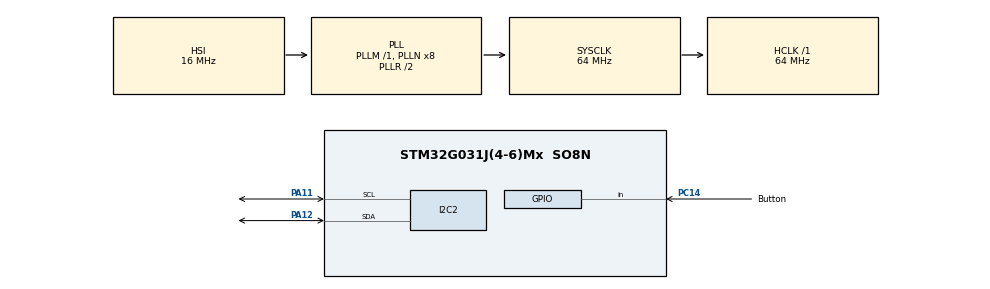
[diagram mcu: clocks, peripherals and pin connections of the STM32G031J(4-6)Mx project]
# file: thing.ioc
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I2C2.Timing=0x10707DBC
Mcu.Family=STM32G0
Mcu.Name=STM32G031J(4-6)Mx
Mcu.Package=SO8N
PA11\ [PA9].Mode=I2C
PA11\ [PA9].Signal=I2C2_SCL
PA12\ [PA10].Mode=I2C
PA12\ [PA10].Signal=I2C2_SDA
PA13.Mode=Serial_Wire
PA13.Signal=SYS_SWDIO
PA14-BOOT0.Mode=Serial_Wire
PA14-BOOT0.Signal=SYS_SWCLK
PA14-BOOT0__PA15__PB5__PB6.StandardMode=true
PB0__PB1__PA8__PA11\ [PA9].StandardMode=true
PC14-OSC32_IN\ (PC14).GPIO_Label=Button
PC14-OSC32_IN\ (PC14).GPIO_PuPd=GPIO_PULLUP
PC14-OSC32_IN\ (PC14).Signal=GPIO_Input
PC14-OSC32_IN\ (PC14)__PB7__PB8__PB9.StandardMode=true
PF2\ -\ NRST__PA0__PA1__PA2.StandardMode=true
ProjectManager.HeapSize=0x200
ProjectManager.StackSize=0x400
ProjectManager.TargetToolchain=Makefile
RCC.ADCFreq_Value=64000000
RCC.AHBFreq_Value=64000000
RCC.CortexFreq_Value=64000000
RCC.EXTERNAL_CLOCK_VALUE=12288000
RCC.HCLKFreq_Value=64000000
RCC.HSE_VALUE=8000000
RCC.HSI_VALUE=16000000
RCC.LSE_VALUE=32768
RCC.SYSCLKFreq_VALUE=64000000
RCC.SYSCLKSource=RCC_SYSCLKSOURCE_PLLCLK
RCC.VCOOutputFreq_Value=128000000
board=custom

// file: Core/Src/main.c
/* USER CODE BEGIN Header */
/**
 ******************************************************************************
 * @file           : main.c
 * @brief          : Main program body
 ******************************************************************************
 * @attention
 *
 * <h2><center>&copy; Copyright (c) 2022 STMicroelectronics.
 * All rights reserved.</center></h2>
 *
 * This software component is licensed by ST under BSD 3-Clause license,
 * the "License"; You may not use this file except in compliance with the
 * License. You may obtain a copy of the License at:
 *                        opensource.org/licenses/BSD-3-Clause
 *
 ******************************************************************************
 */
/* USER CODE END Header */
#include "main.h"

/* USER CODE BEGIN PD */
#define TEXTSPLASH
/* USER CODE END PD */

I2C_HandleTypeDef hi2c2;

void SystemClock_Config(void);
static void MX_GPIO_Init(void);
static void MX_I2C2_Init(void);

void SystemClock_Config(void)
{
  RCC_OscInitTypeDef RCC_OscInitStruct = {0};
  RCC_ClkInitTypeDef RCC_ClkInitStruct = {0};

  /** Configure the main internal regulator output voltage
   */
  HAL_PWREx_ControlVoltageScaling(PWR_REGULATOR_VOLTAGE_SCALE1);
  /** Initializes the RCC Oscillators according to the specified parameters
   * in the RCC_OscInitTypeDef structure.
   */
  RCC_OscInitStruct.OscillatorType = RCC_OSCILLATORTYPE_HSI;
  RCC_OscInitStruct.HSIState = RCC_HSI_ON;
  RCC_OscInitStruct.HSIDiv = RCC_HSI_DIV1;
  RCC_OscInitStruct.HSICalibrationValue = RCC_HSICALIBRATION_DEFAULT;
  RCC_OscInitStruct.PLL.PLLState = RCC_PLL_ON;
  RCC_OscInitStruct.PLL.PLLSource = RCC_PLLSOURCE_HSI;
  RCC_OscInitStruct.PLL.PLLM = RCC_PLLM_DIV1;
  RCC_OscInitStruct.PLL.PLLN = 8;
  RCC_OscInitStruct.PLL.PLLP = RCC_PLLP_DIV2;
  RCC_OscInitStruct.PLL.PLLQ = RCC_PLLQ_DIV2;
  RCC_OscInitStruct.PLL.PLLR = RCC_PLLR_DIV2;
  if (HAL_RCC_OscConfig(&RCC_OscInitStruct) != HAL_OK)
  {
    Error_Handler();
  }
  /** Initializes the CPU, AHB and APB buses clocks
   */
  RCC_ClkInitStruct.ClockType = RCC_CLOCKTYPE_HCLK | RCC_CLOCKTYPE_SYSCLK | RCC_CLOCKTYPE_PCLK1;
  RCC_ClkInitStruct.SYSCLKSource = RCC_SYSCLKSOURCE_PLLCLK;
  RCC_ClkInitStruct.AHBCLKDivider = RCC_SYSCLK_DIV1;
  RCC_ClkInitStruct.APB1CLKDivider = RCC_HCLK_DIV1;

  if (HAL_RCC_ClockConfig(&RCC_ClkInitStruct, FLASH_LATENCY_2) != HAL_OK)
  {
    Error_Handler();
  }
}

static void MX_I2C2_Init(void)
{

  hi2c2.Instance = I2C2;
  hi2c2.Init.Timing = 0x10707DBC;
  hi2c2.Init.OwnAddress1 = 0;
  hi2c2.Init.AddressingMode = I2C_ADDRESSINGMODE_7BIT;
  hi2c2.Init.DualAddressMode = I2C_DUALADDRESS_DISABLE;
  hi2c2.Init.OwnAddress2 = 0;
  hi2c2.Init.OwnAddress2Masks = I2C_OA2_NOMASK;
  hi2c2.Init.GeneralCallMode = I2C_GENERALCALL_DISABLE;
  hi2c2.Init.NoStretchMode = I2C_NOSTRETCH_DISABLE;
  if (HAL_I2C_Init(&hi2c2) != HAL_OK)
  {
    Error_Handler();
  }
  /** Configure Analogue filter
   */
  if (HAL_I2CEx_ConfigAnalogFilter(&hi2c2, I2C_ANALOGFILTER_ENABLE) != HAL_OK)
  {
    Error_Handler();
  }
  /** Configure Digital filter
   */
  if (HAL_I2CEx_ConfigDigitalFilter(&hi2c2, 0) != HAL_OK)
  {
    Error_Handler();
  }
}

static void MX_GPIO_Init(void)
{
  GPIO_InitTypeDef GPIO_InitStruct = {0};

  /* GPIO Ports Clock Enable */
  __HAL_RCC_GPIOC_CLK_ENABLE();
  __HAL_RCC_GPIOA_CLK_ENABLE();

  /*Configure GPIO pin : Button_Pin */
  GPIO_InitStruct.Pin = Button_Pin;
  GPIO_InitStruct.Mode = GPIO_MODE_INPUT;
  GPIO_InitStruct.Pull = GPIO_PULLUP;
  HAL_GPIO_Init(Button_GPIO_Port, &GPIO_InitStruct);
}

/* USER CODE BEGIN 4 */
void thingInit(void)
{
  HAL_Init();

  SystemClock_Config();

  MX_GPIO_Init();
  MX_I2C2_Init();
  // MX_DMA_Init();
  ssd1306Begin(SSD1306_SWITCHCAPVCC, thingPort(), 128, 32);

#ifdef SPLASH
  drawBitmap(0, 0, splashScreen, 128, 32, WHITE);
  flushDisplay();
  HAL_Delay(2500);
  clearDisplay();
#endif

#ifdef TEXTSPLASH
  printf("i2c thing\nfw built %s\n", __DATE__);
  flushDisplay();
  setCursor(0, 0);
  HAL_Delay(2500);
  clearDisplay();
#endif
}

int __io_putchar(int ch)
{
  writeChar(ch);
  return ch;
}

uint8_t readButton(void)
{
  if (HAL_GPIO_ReadPin(Button_GPIO_Port, Button_Pin))
    return 0;
  return 1;
}

I2C_HandleTypeDef *thingPort(void)
{
  return &hi2c2;
}

void printFloat(float v, int decimalDigits, char s[])
{
  int i = 1;
  int intPart, fractPart;
  for (; decimalDigits != 0; i *= 10, decimalDigits--)
    ;
  intPart = (int)v;
  fractPart = (int)((v - (float)(int)v) * i);
  if (fractPart < 0)
    fractPart *= -1;
  sprintf(s, "%i.%i", intPart, fractPart);
}
/* USER CODE END 4 */

void Error_Handler(void)
{
  __disable_irq();
  while (1)
  {
  }
}

/************************ (C) COPYRIGHT STMicroelectronics *****END OF FILE****/
